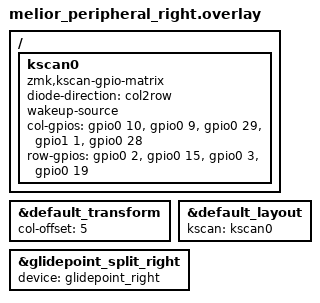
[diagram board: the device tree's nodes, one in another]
#include "melior.dtsi"

/ {
    kscan0: kscan0 {
        compatible = "zmk,kscan-gpio-matrix";
        diode-direction = "col2row"; 
        wakeup-source;

        col-gpios
            = <&gpio0 10 GPIO_ACTIVE_HIGH> //Col 4
            , <&gpio0 9 GPIO_ACTIVE_HIGH> //Col 3
            , <&gpio0 29 GPIO_ACTIVE_HIGH> //Col 2
            , <&gpio1 1 GPIO_ACTIVE_HIGH> //Col 1
            , <&gpio0 28 GPIO_ACTIVE_HIGH> //Col 0
            ;

        row-gpios
            = <&gpio0 2 (GPIO_ACTIVE_HIGH | GPIO_PULL_DOWN)> //Row 0
            , <&gpio0 15 (GPIO_ACTIVE_HIGH | GPIO_PULL_DOWN)> //Row 1
            , <&gpio0 3 (GPIO_ACTIVE_HIGH | GPIO_PULL_DOWN)> //Row 2
            , <&gpio0 19 (GPIO_ACTIVE_HIGH | GPIO_PULL_DOWN)> //Row 3
            ;
    };
};

&default_transform {
    col-offset = <5>;
};

&default_layout {
    kscan = <&kscan0>;        
};

// == Input devices ==
// Enabling input-split for its own input devices
// Adding input devices and assigning them to input-split
&glidepoint_split_right {
    status = "okay";
    device = <&glidepoint_right>;
};

